# PIC18LF4331 register map
Vendor: Microchip
Registers are 8-bit, read-write, reset 0x0 unless marked. A register's access mark holds for its fields unless they carry their own. Addresses are absolute, and some are shared; only a register's first bit layout is shown; [hi:lo] are bit positions; {n}, {i} and the like mark numbered series.

## SFR
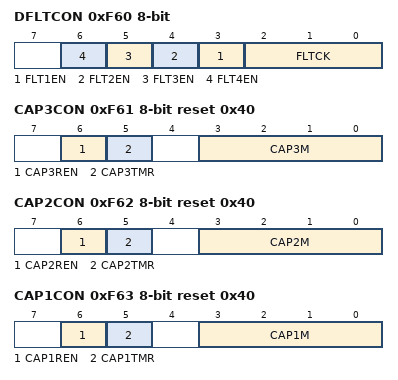
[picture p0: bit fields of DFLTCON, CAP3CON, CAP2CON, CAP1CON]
0xF60 DFLTCON
  [n+2] FLT{n}EN (n=1..4), [2:0] FLTCK
0xF61 CAP3CON reset 0x40
  [6] CAP3REN, [5] CAP3TMR, [3:0] CAP3M
0xF62 CAP2CON reset 0x40
  [6] CAP2REN, [5] CAP2TMR, [3:0] CAP2M
0xF63 CAP1CON reset 0x40
  [6] CAP1REN, [5] CAP1TMR, [3:0] CAP1M
0xF64 CAP3BUFL reset not defined — (power-on value xxxxxxxx)
0xF65 CAP3BUFH reset not defined — (power-on value xxxxxxxx)
0xF66 CAP2BUFL reset not defined — (power-on value xxxxxxxx)
0xF67 CAP2BUFH reset not defined — (power-on value xxxxxxxx)
0xF68 CAP1BUFL reset not defined — (power-on value xxxxxxxx)
0xF69 CAP1BUFH reset not defined — (power-on value xxxxxxxx)
0xF6A OVDCONS
  [7:0] POUT
0xF6B OVDCOND reset 0xFF
  [7:0] POVD
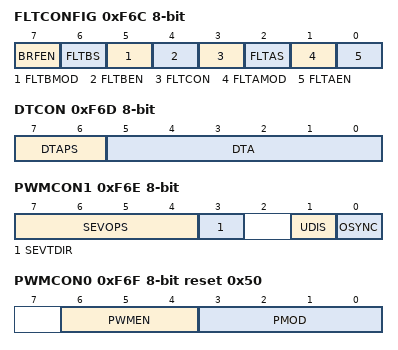
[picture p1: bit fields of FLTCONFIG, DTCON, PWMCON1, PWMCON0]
0xF6C FLTCONFIG
  [7] BRFEN, [6] FLTBS, [5] FLTBMOD, [4] FLTBEN, [3] FLTCON, [2] FLTAS, [1] FLTAMOD, [0] FLTAEN
0xF6D DTCON
  [7:6] DTAPS, [5:0] DTA
0xF6E PWMCON1
  [7:4] SEVOPS, [3] SEVTDIR, [1] UDIS, [0] OSYNC
0xF6F PWMCON0 reset 0x50
  [6:4] PWMEN, [3:0] PMOD
0xF70 SEVTCMPH
  [3:0] SEVTCMPH
0xF71 SEVTCMPL
0xF72 PDC3H
  [5:0] PDC3H
0xF73 PDC3L
0xF74 PDC2H
  [5:0] PDC2H
0xF75 PDC2L
0xF76 PDC1H
  [5:0] PDC1H
0xF77 PDC1L
0xF78 PDC0H
  [5:0] PDC0H
0xF79 PDC0L
0xF7A PTPERH reset 0xF
  [3:0] PTPERH
0xF7B PTPERL reset 0xFF
0xF7C PTMRH
  [3:0] PTMRH
0xF7D PTMRL
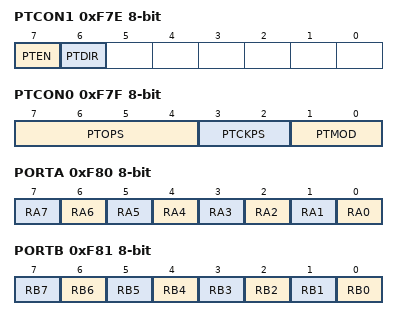
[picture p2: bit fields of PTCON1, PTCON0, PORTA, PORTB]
0xF7E PTCON1
  [7] PTEN, [6] PTDIR ro
0xF7F PTCON0
  [7:4] PTOPS, [3:2] PTCKPS, [1:0] PTMOD
0xF80 PORTA reset not defined — (power-on value xx000000)
  [n] RA{n} (n=0..7)
0xF81 PORTB reset not defined — (power-on value xxxxxxxx)
  [n] RB{n} (n=0..7)
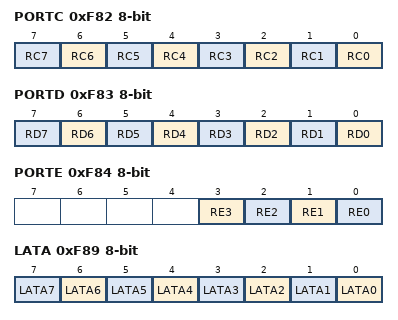
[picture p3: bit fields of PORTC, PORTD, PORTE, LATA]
0xF82 PORTC reset not defined — (power-on value xxxxxxxx)
  [n] RC{n} (n=0..7)
0xF83 PORTD reset not defined — (power-on value xxxxxxxx)
  [n] RD{n} (n=0..7)
0xF84 PORTE reset not defined — (power-on value ----x000)
  [3] RE3 ro, [2] RE2, [1] RE1, [0] RE0
0xF87 TMR5L reset not defined — (power-on value xxxxxxxx)
0xF88 TMR5H reset not defined — (power-on value xxxxxxxx)
0xF89 LATA reset not defined — (power-on value xxxxxxxx)
  [n] LATA{n} (n=0..7)
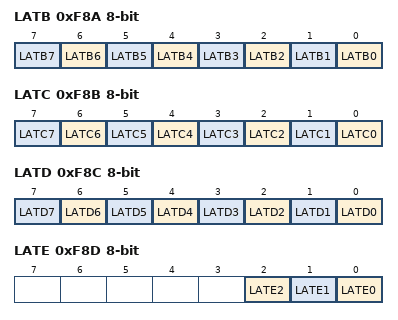
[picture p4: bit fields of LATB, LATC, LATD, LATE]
0xF8A LATB reset not defined — (power-on value xxxxxxxx)
  [n] LATB{n} (n=0..7)
0xF8B LATC reset not defined — (power-on value xxxxxxxx)
  [n] LATC{n} (n=0..7)
0xF8C LATD reset not defined — (power-on value xxxxxxxx)
  [n] LATD{n} (n=0..7)
0xF8D LATE reset not defined — (power-on value -----xxx)
  [2] LATE2, [1] LATE1, [0] LATE0
0xF90 PR5L reset 0xFF
0xF91 PR5H reset 0xFF
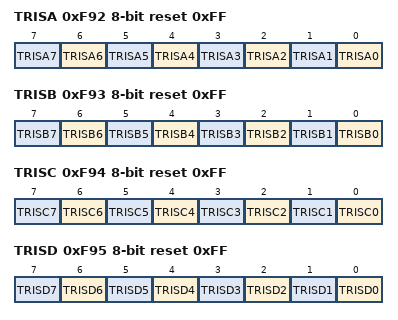
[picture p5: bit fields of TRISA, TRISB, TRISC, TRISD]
0xF92 TRISA reset 0xFF
  [n] TRISA{n} (n=0..7)
0xF93 TRISB reset 0xFF
  [n] TRISB{n} (n=0..7)
0xF94 TRISC reset 0xFF
  [n] TRISC{n} (n=0..7)
0xF95 TRISD reset 0xFF
  [n] TRISD{n} (n=0..7)
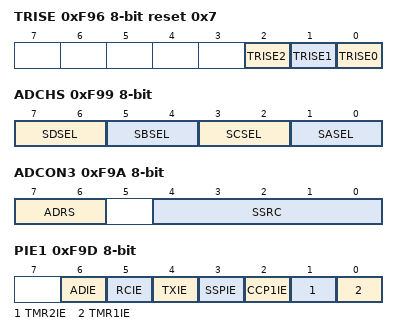
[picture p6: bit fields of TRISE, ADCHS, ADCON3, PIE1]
0xF96 TRISE reset 0x7
  [2] TRISE2, [1] TRISE1, [0] TRISE0
0xF99 ADCHS
  [7:6] SDSEL, [5:4] SBSEL, [3:2] SCSEL, [1:0] SASEL
0xF9A ADCON3
  [7:6] ADRS, [4:0] SSRC
0xF9B OSCTUNE
  [5:0] TUN
0xF9D PIE1
  [6] ADIE, [5] RCIE, [4] TXIE, [3] SSPIE, [2] CCP1IE, [1] TMR2IE, [0] TMR1IE
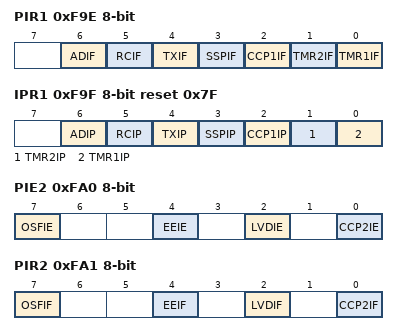
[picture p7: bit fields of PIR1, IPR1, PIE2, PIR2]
0xF9E PIR1
  [6] ADIF, [5] RCIF ro, [4] TXIF ro, [3] SSPIF, [2] CCP1IF, [1] TMR2IF, [0] TMR1IF
0xF9F IPR1 reset 0x7F
  [6] ADIP, [5] RCIP, [4] TXIP, [3] SSPIP, [2] CCP1IP, [1] TMR2IP, [0] TMR1IP
0xFA0 PIE2
  [7] OSFIE, [4] EEIE, [2] LVDIE, [0] CCP2IE
0xFA1 PIR2
  [7] OSFIF, [4] EEIF, [2] LVDIF, [0] CCP2IF
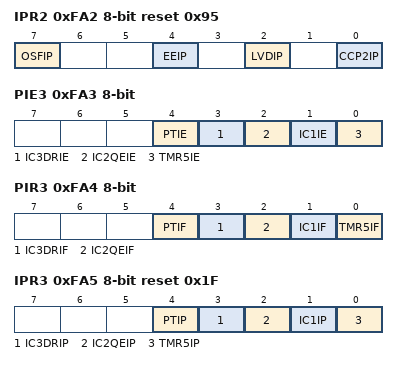
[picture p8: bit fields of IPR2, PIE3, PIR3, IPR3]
0xFA2 IPR2 reset 0x95
  [7] OSFIP, [4] EEIP, [2] LVDIP, [0] CCP2IP
0xFA3 PIE3
  [4] PTIE, [3] IC3DRIE, [2] IC2QEIE, [1] IC1IE, [0] TMR5IE
0xFA4 PIR3
  [4] PTIF, [3] IC3DRIF, [2] IC2QEIF, [1] IC1IF, [0] TMR5IF
0xFA5 IPR3 reset 0x1F
  [4] PTIP, [3] IC3DRIP, [2] IC2QEIP, [1] IC1IP, [0] TMR5IP
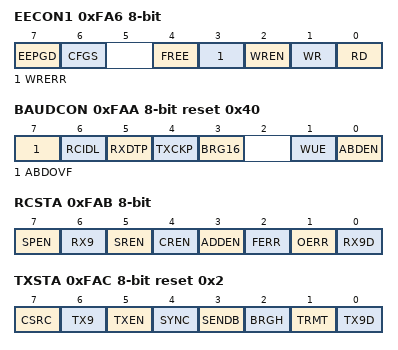
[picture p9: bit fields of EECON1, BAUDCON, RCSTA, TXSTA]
0xFA6 EECON1 reset not defined — (power-on value xx-0x000)
  [7] EEPGD
  [6] CFGS
  [4] FREE
  [3] WRERR
  [2] WREN
  [1] WR — (can only be set)
  [0] RD — (can only be set)
0xFA7 EECON2 wo reset not defined
0xFA8 EEDATA reset not defined — (power-on value xxxxxxxx)
0xFA9 EEADR reset not defined — (power-on value xxxxxxxx)
0xFAA BAUDCON reset 0x40
  [7] ABDOVF — (can only be cleared)
  [6] RCIDL ro
  [5] RXDTP
  [4] TXCKP
  [3] BRG16
  [1] WUE
  [0] ABDEN
0xFAB RCSTA reset not defined — (power-on value 0000000x)
  [7] SPEN, [6] RX9, [5] SREN, [4] CREN, [3] ADDEN, [2] FERR ro, [1] OERR ro, [0] RX9D ro
0xFAC TXSTA reset 0x2
  [7] CSRC, [6] TX9, [5] TXEN, [4] SYNC, [3] SENDB, [2] BRGH, [1] TRMT ro, [0] TX9D
0xFAD TXREG wo
0xFAE RCREG ro
0xFAF SPBRG
0xFB0 SPBRGH
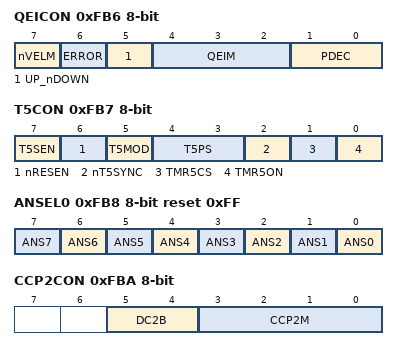
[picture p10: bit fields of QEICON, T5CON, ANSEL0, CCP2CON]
0xFB6 QEICON
  [7] nVELM, [6] ERROR, [5] UP_nDOWN, [4:2] QEIM, [1:0] PDEC
0xFB7 T5CON
  [7] T5SEN, [6] nRESEN, [5] T5MOD, [4:3] T5PS, [2] nT5SYNC, [1] TMR5CS, [0] TMR5ON
0xFB8 ANSEL0 reset 0xFF
  [n] ANS{n} (n=0..7)
0xFB9 ANSEL1 reset 0x1
  [0] ANS8
0xFBA CCP2CON
  [5:4] DC2B, [3:0] CCP2M
0xFBB CCPR2L reset not defined — (power-on value xxxxxxxx)
0xFBC CCPR2H reset not defined — (power-on value xxxxxxxx)
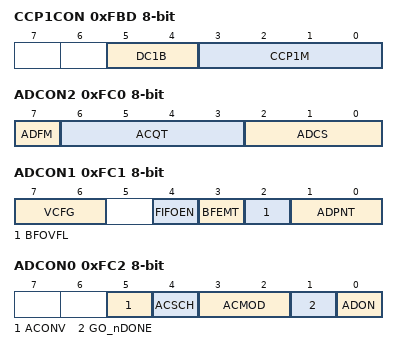
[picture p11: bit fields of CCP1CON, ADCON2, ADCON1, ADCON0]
0xFBD CCP1CON
  [5:4] DC1B, [3:0] CCP1M
0xFBE CCPR1L reset not defined — (power-on value xxxxxxxx)
0xFBF CCPR1H reset not defined — (power-on value xxxxxxxx)
0xFC0 ADCON2
  [7] ADFM, [6:3] ACQT, [2:0] ADCS
0xFC1 ADCON1
  [7:6] VCFG, [4] FIFOEN, [3] BFEMT ro, [2] BFOVFL ro, [1:0] ADPNT ro
0xFC2 ADCON0
  [5] ACONV, [4] ACSCH, [3:2] ACMOD, [1] GO_nDONE, [0] ADON
0xFC3 ADRESL reset not defined — (power-on value xxxxxxxx)
0xFC4 ADRESH reset not defined — (power-on value xxxxxxxx)
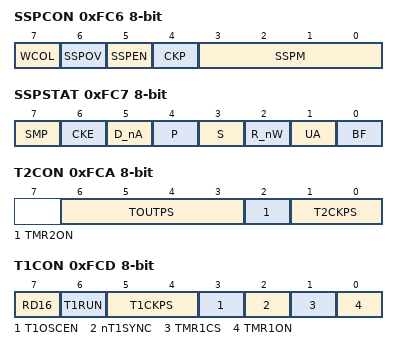
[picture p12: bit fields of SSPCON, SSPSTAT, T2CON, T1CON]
0xFC6 SSPCON
  [7] WCOL, [6] SSPOV, [5] SSPEN, [4] CKP, [3:0] SSPM
0xFC7 SSPSTAT
  [7] SMP, [6] CKE, [5] D_nA, [4] P, [3] S, [2] R_nW, [1] UA, [0] BF
0xFC8 SSPADD
0xFC9 SSPBUF reset not defined — (power-on value xxxxxxxx)
0xFCA T2CON
  [6:3] TOUTPS, [2] TMR2ON, [1:0] T2CKPS
0xFCB PR2 reset 0xFF
0xFCC TMR2
0xFCD T1CON
  [7] RD16, [6] T1RUN, [5:4] T1CKPS, [3] T1OSCEN ro, [2] nT1SYNC ro, [1] TMR1CS, [0] TMR1ON
0xFCE TMR1L reset not defined — (power-on value xxxxxxxx)
0xFCF TMR1H reset not defined — (power-on value xxxxxxxx)
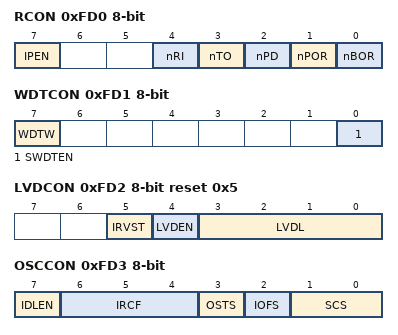
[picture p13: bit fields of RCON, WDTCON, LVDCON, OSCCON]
0xFD0 RCON reset not defined — (power-on value 0--111qq)
  [7] IPEN, [4] nRI, [3] nTO, [2] nPD, [1] nPOR, [0] nBOR
0xFD1 WDTCON
  [7] WDTW ro, [0] SWDTEN
0xFD2 LVDCON reset 0x5
  [5] IRVST, [4] LVDEN, [3:0] LVDL
0xFD3 OSCCON
  [7] IDLEN, [6:4] IRCF, [3] OSTS ro, [2] IOFS ro, [1:0] SCS
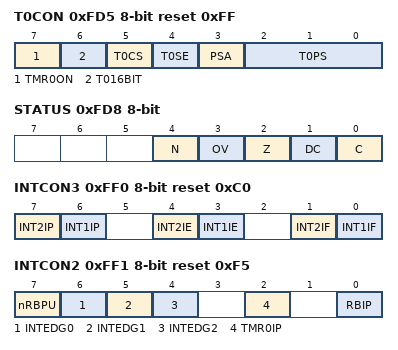
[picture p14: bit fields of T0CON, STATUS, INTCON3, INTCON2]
0xFD5 T0CON reset 0xFF
  [7] TMR0ON, [6] T016BIT, [5] T0CS, [4] T0SE, [3] PSA, [2:0] T0PS
0xFD6 TMR0L reset not defined — (power-on value xxxxxxxx)
0xFD7 TMR0H
0xFD8 STATUS reset not defined — (power-on value ---xxxxx)
  [4] N, [3] OV, [2] Z, [1] DC, [0] C
0xFD9 FSR2L reset not defined — (power-on value xxxxxxxx)
0xFDA FSR2H
  [3:0] FSR2H
0xFDB PLUSW2 access not given reset not defined
0xFDC PREINC2 access not given reset not defined
0xFDD POSTDEC2 access not given reset not defined
0xFDE POSTINC2 access not given reset not defined
0xFDF INDF2 access not given reset not defined
0xFE0 BSR
  [3:0] BSR
0xFE1 FSR1L reset not defined — (power-on value xxxxxxxx)
0xFE2 FSR1H
  [3:0] FSR1H
0xFE3 PLUSW1 access not given reset not defined
0xFE4 PREINC1 access not given reset not defined
0xFE5 POSTDEC1 access not given reset not defined
0xFE6 POSTINC1 access not given reset not defined
0xFE7 INDF1 access not given reset not defined
0xFE8 WREG reset not defined — (power-on value xxxxxxxx)
0xFE9 FSR0L reset not defined — (power-on value xxxxxxxx)
0xFEA FSR0H
  [3:0] FSR0H
0xFEB PLUSW0 access not given reset not defined
0xFEC PREINC0 access not given reset not defined
0xFED POSTDEC0 access not given reset not defined
0xFEE POSTINC0 access not given reset not defined
0xFEF INDF0 access not given reset not defined
0xFF0 INTCON3 reset 0xC0
  [7] INT2IP, [6] INT1IP, [4] INT2IE, [3] INT1IE, [1] INT2IF, [0] INT1IF
0xFF1 INTCON2 reset 0xF5
  [7] nRBPU, [6] INTEDG0, [5] INTEDG1, [4] INTEDG2, [2] TMR0IP, [0] RBIP
0xFF2 INTCON reset not defined — (power-on value 0000000x)
  [7] GIE_GIEH, [6] PEIE_GIEL, [5] TMR0IE, [4] INT0IE, [3] RBIE, [2] TMR0IF, [1] INT0IF, [0] RBIF
0xFF3 PRODL reset not defined — (power-on value xxxxxxxx)
0xFF4 PRODH reset not defined — (power-on value xxxxxxxx)
0xFF5 TABLAT
0xFF6 TBLPTRL
0xFF7 TBLPTRH
0xFF8 TBLPTRU
  [5] ACSS, [4:0] TBLPTRU
0xFF9 PCL
0xFFA PCLATH
  [7:0] PCH
0xFFB PCLATU
  [4:0] PCU
0xFFC STKPTR
  [7] STKFUL — (can only be cleared)
  [6] STKUNF — (can only be cleared)
  [4:0] STKPTR
0xFFD TOSL
0xFFE TOSH
0xFFF TOSU
  [4:0] TOSU
